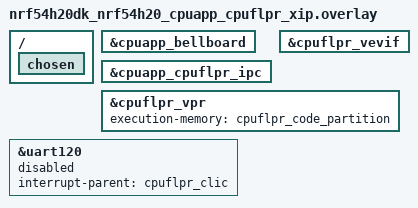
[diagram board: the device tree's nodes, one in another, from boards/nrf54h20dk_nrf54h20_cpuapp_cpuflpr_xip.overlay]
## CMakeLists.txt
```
#
# Copyright (c) 2025 Nordic Semiconductor ASA
#
# SPDX-License-Identifier: Apache-2.0
#

cmake_minimum_required(VERSION 3.20.0)

find_package(Zephyr REQUIRED HINTS $ENV{ZEPHYR_BASE})
project(zbus_ipc_forwarder)

zephyr_library_include_directories(
  src
  common
)

# Define which device this is
zephyr_compile_definitions(ZBUS_DEVICE_A=1)

target_sources(app PRIVATE src/main.c)
```

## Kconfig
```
#
# Copyright (c) 2025 Nordic Semiconductor ASA
#
# SPDX-License-Identifier: Apache-2.0
#

source "Kconfig.zephyr"
```

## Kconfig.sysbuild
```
#
# Copyright (c) 2025 Nordic Semiconductor ASA
#
# SPDX-License-Identifier: Apache-2.0
#

source "share/sysbuild/Kconfig"

choice
	prompt "Remote board target"
	default REMOTE_BOARD_NRF54H20_CPURAD if BOARD = "nrf54h20dk"
	default REMOTE_BOARD_NRF5340_CPUNET if BOARD = "nrf5340dk"

config REMOTE_BOARD_NRF54H20_CPURAD
	bool "nrf54h20dk/nrf54h20/cpurad"

config REMOTE_BOARD_NRF54H20_CPUPPR
	bool "nrf54h20dk/nrf54h20/cpuppr"

config REMOTE_BOARD_NRF54H20_CPUPPR_XIP
	bool "nrf54h20dk/nrf54h20/cpuppr/xip"

## Do not fit on nRF54H20_CPUFLPR without XIP

config REMOTE_BOARD_NRF54H20_CPUFLPR_XIP
	bool "nrf54h20dk/nrf54h20/cpuflpr/xip"

config REMOTE_BOARD_NRF5340_CPUNET
	bool "nrf5340dk/nrf5340/cpunet"

endchoice

config REMOTE_BOARD
	string "The board used for remote target"
	default "nrf54h20dk/nrf54h20/cpurad" if REMOTE_BOARD_NRF54H20_CPURAD
	default "nrf54h20dk/nrf54h20/cpuppr" if REMOTE_BOARD_NRF54H20_CPUPPR
	default "nrf54h20dk/nrf54h20/cpuppr/xip" if REMOTE_BOARD_NRF54H20_CPUPPR_XIP
	default "nrf54h20dk/nrf54h20/cpuflpr/xip" if REMOTE_BOARD_NRF54H20_CPUFLPR_XIP
	default "nrf5340dk/nrf5340/cpunet" if REMOTE_BOARD_NRF5340_CPUNET
```

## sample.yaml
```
sample:
  name: IPC Forwarder
  description: Sample application demonstrating Zbus IPC forwarder functionality.
tests:
  sample.zbus.ipc_forwarder.nrf54h20_cpuapp_cpurad:
    sysbuild: true
    platform_allow:
      - nrf54h20dk/nrf54h20/cpuapp
    extra_args:
      - SNIPPET=nordic-log-stm
      - SB_CONFIG_REMOTE_BOARD_NRF54H20_CPURAD=y
    timeout: 30
    harness: console
    harness_config:
      type: multi_line
      ordered: false
      regex:
        - ".* app/main: Channel request_channel is a master channel"
        - ".* app/main: Channel response_channel is a shadow channel"
        - ".* rad/main: Channel request_channel is a shadow channel"
        - ".* rad/main: Channel response_channel is a master channel"
        - ".* app/main: Published on channel request_channel. Request ID=1, Min=-1, Max=1"
        - ".* rad/main: Received message on channel request_channel"
        - ".* rad/main: Request ID: 1, Min: -1, Max: 1"
        - ".* rad/main: Sending response: ID=1, Value=.*"
        - ".* rad/main: Response published on channel response_channel"
        - ".* app/main: Received message on channel response_channel"
        - ".* app/main: Response ID: 1, Value: .*"

  sample.zbus.ipc_forwarder.nrf54h20_cpuapp_cpuppr:
    sysbuild: true
    platform_allow:
      - nrf54h20dk/nrf54h20/cpuapp
    extra_args:
      - SNIPPET=nordic-log-stm
      - SB_CONFIG_REMOTE_BOARD_NRF54H20_CPUPPR=y
    timeout: 30
    harness: console
    harness_config:
      type: multi_line
      ordered: false
      regex:
        - ".* app/main: Channel request_channel is a master channel"
        - ".* app/main: Channel response_channel is a shadow channel"
        - ".* ppr/main: Channel request_channel is a shadow channel"
        - ".* ppr/main: Channel response_channel is a master channel"
        - ".* app/main: Published on channel request_channel. Request ID=1, Min=-1, Max=1"
        - ".* ppr/main: Received message on channel request_channel"
        - ".* ppr/main: Request ID: 1, Min: -1, Max: 1"
        - ".* ppr/main: Sending response: ID=1, Value=.*"
        - ".* ppr/main: Response published on channel response_channel"
        - ".* app/main: Received message on channel response_channel"
        - ".* app/main: Response ID: 1, Value: .*"

  sample.zbus.ipc_forwarder.nrf54h20_cpuapp_cpuppr_xip:
    sysbuild: true
    platform_allow:
      - nrf54h20dk/nrf54h20/cpuapp
    extra_args:
      - SNIPPET=nordic-log-stm
      - SB_CONFIG_REMOTE_BOARD_NRF54H20_CPUPPR_XIP=y
    timeout: 30
    harness: console
    harness_config:
      type: multi_line
      ordered: false
      regex:
        - ".* app/main: Channel request_channel is a master channel"
        - ".* app/main: Channel response_channel is a shadow channel"
        - ".* ppr/main: Channel request_channel is a shadow channel"
        - ".* ppr/main: Channel response_channel is a master channel"
        - ".* app/main: Published on channel request_channel. Request ID=1, Min=-1, Max=1"
        - ".* ppr/main: Received message on channel request_channel"
        - ".* ppr/main: Request ID: 1, Min: -1, Max: 1"
        - ".* ppr/main: Sending response: ID=1, Value=.*"
        - ".* ppr/main: Response published on channel response_channel"
        - ".* app/main: Received message on channel response_channel"
        - ".* app/main: Response ID: 1, Value: .*"

  sample.zbus.ipc_forwarder.nrf54h20_cpuapp_cpuflpr_xip:
    sysbuild: true
    platform_allow:
      - nrf54h20dk/nrf54h20/cpuapp
    extra_args:
      - SNIPPET=nordic-log-stm
      - SB_CONFIG_REMOTE_BOARD_NRF54H20_CPUFLPR_XIP=y
    timeout: 30
    harness: console
    harness_config:
      type: multi_line
      ordered: false
      regex:
        - ".* app/main: Channel request_channel is a master channel"
        - ".* app/main: Channel response_channel is a shadow channel"
        - ".* flpr/main: Channel request_channel is a shadow channel"
        - ".* flpr/main: Channel response_channel is a master channel"
        - ".* app/main: Published on channel request_channel. Request ID=1, Min=-1, Max=1"
        - ".* flpr/main: Received message on channel request_channel"
        - ".* flpr/main: Request ID: 1, Min: -1, Max: 1"
        - ".* flpr/main: Sending response: ID=1, Value=.*"
        - ".* flpr/main: Response published on channel response_channel"
        - ".* app/main: Received message on channel response_channel"
        - ".* app/main: Response ID: 1, Value: .*"

  sample.zbus.ipc_forwarder.nrf5340_cpuapp_cpunet:
    sysbuild: true
    platform_allow:
      - nrf5340dk/nrf5340/cpuapp
      - nrf5340bsim/nrf5340/cpuapp
    integration_platforms:
      - nrf5340bsim/nrf5340/cpuapp
    tags: ipc
    timeout: 30
    harness: console
    harness_config:
      type: multi_line
      ordered: false
      regex:
        - ".* main: Channel request_channel is a master channel"
        - ".* main: Channel response_channel is a shadow channel"
        - ".* main: Published on channel request_channel. Request ID=1, Min=-1, Max=1"
        - ".* main: Received message on channel response_channel"
        - ".* main: Response ID: 1, Value: .*"
```

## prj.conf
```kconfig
#
# Copyright (c) 2025 Nordic Semiconductor ASA
#
# SPDX-License-Identifier: Apache-2.0
#

CONFIG_LOG=y
# CONFIG_LOG_MODE_MINIMAL=y
CONFIG_LOG_DBG_COLOR_BLUE=y

CONFIG_HEAP_MEM_POOL_SIZE=4096

CONFIG_ZBUS=y
CONFIG_ZBUS_CHANNEL_NAME=y
CONFIG_ZBUS_MSG_SUBSCRIBER=y

CONFIG_CRC=y

CONFIG_MBOX=y
CONFIG_IPC_SERVICE=y

CONFIG_ZBUS_MULTIDOMAIN=y
CONFIG_ZBUS_MULTIDOMAIN_IPC=y
CONFIG_ZBUS_MULTIDOMAIN_LOG_LEVEL_INF=y

# Increase the size of the receive buffer to accommodate larger messages
CONFIG_PBUF_RX_READ_BUF_SIZE=384
```

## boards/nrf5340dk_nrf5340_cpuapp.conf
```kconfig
#
# Copyright (c) 2025 Nordic Semiconductor ASA
#
# SPDX-License-Identifier: Apache-2.0
#

CONFIG_SOC_NRF53_CPUNET_ENABLE=y
```

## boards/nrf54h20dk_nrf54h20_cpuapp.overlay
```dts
/*
 * Copyright (c) 2025 Nordic Semiconductor ASA
 *
 * SPDX-License-Identifier: Apache-2.0
 */

&cpuapp_bellboard {
	status = "okay";
};

/ {
	chosen {
		/delete-property/ zephyr,bt-hci;
	};
};
```

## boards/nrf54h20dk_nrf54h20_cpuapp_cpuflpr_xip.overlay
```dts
/*
 * Copyright (c) 2025 Nordic Semiconductor ASA
 *
 * SPDX-License-Identifier: Apache-2.0
 */

 /* Setup for cpuapp_cpuflpr_ipc */
&cpuapp_bellboard {
	status = "okay";
};

/delete-node/ &cpuapp_cpurad_ipc;

ipc0: &cpuapp_cpuflpr_ipc {
	status = "okay";
};

&cpuflpr_vevif {
	status = "okay";
};

/ {
	chosen {
		/delete-property/ zephyr,bt-hci;
	};
};

/* Necessary for the cpuflpr_xip to work */
&cpuflpr_vpr {
	status = "okay";
	execution-memory = <&cpuflpr_code_partition>;
	/delete-property/ source-memory;
};

&uart120 {
	status = "reserved";
	interrupt-parent = <&cpuflpr_clic>;
};
```

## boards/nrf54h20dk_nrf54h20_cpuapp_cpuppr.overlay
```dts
/*
 * Copyright (c) 2025 Nordic Semiconductor ASA
 *
 * SPDX-License-Identifier: Apache-2.0
 */

 /* Setup for cpuapp_cpuppr_ipc */
&cpuapp_bellboard {
	status = "okay";
};

/delete-node/ &cpuapp_cpurad_ipc;

ipc0: &cpuapp_cpuppr_ipc {
	status = "okay";
};

&cpuppr_vevif {
	status = "okay";
};

/ {
	chosen {
		/delete-property/ zephyr,bt-hci;
	};
};

/* Necessary for the cpuppr to work */
&cpuppr_vpr {
	status = "okay";
};

&uart135 {
	status = "reserved";
};
```

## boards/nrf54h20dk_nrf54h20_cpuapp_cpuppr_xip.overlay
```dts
/*
 * Copyright (c) 2025 Nordic Semiconductor ASA
 *
 * SPDX-License-Identifier: Apache-2.0
 */

 /* Setup for cpuapp_cpuppr_ipc */
&cpuapp_bellboard {
	status = "okay";
};

/delete-node/ &cpuapp_cpurad_ipc;

ipc0: &cpuapp_cpuppr_ipc {
	status = "okay";
};

&cpuppr_vevif {
	status = "okay";
};

/ {
	chosen {
		/delete-property/ zephyr,bt-hci;
	};
};

/* Necessary for the cpuppr_xip to work */
&cpuppr_vpr {
	status = "okay";
	execution-memory = <&cpuppr_code_partition>;
	/delete-property/ source-memory;
};

&uart135 {
	status = "reserved";
};
```

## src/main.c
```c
/*
 * Copyright (c) 2025 Nordic Semiconductor ASA
 *
 * SPDX-License-Identifier: Apache-2.0
 */

#include <zephyr/kernel.h>
#include <zephyr/logging/log.h>
#include <string.h>
#include <zephyr/zbus/zbus.h>
#include <zephyr/zbus/multidomain/zbus_multidomain.h>

#include "common.h"

LOG_MODULE_REGISTER(main, LOG_LEVEL_DBG);

/* NOTE: Shared channels request_channel and response_channel are defined in common.h */

/* Set up proxy agent for ipc0 and add response channel to be forwarded */
#define IPC0_NODE DT_NODELABEL(ipc0)
ZBUS_PROXY_AGENT_DEFINE(ipc_proxy, ZBUS_MULTIDOMAIN_TYPE_IPC, IPC0_NODE);
ZBUS_PROXY_ADD_CHANNEL(ipc_proxy, request_channel);

/* Log response data coming from the response channel */
void ipc_forwarder_listener_cb(const struct zbus_channel *chan)
{
	const struct response_data *data = zbus_chan_const_msg(chan);

	LOG_INF("Received message on channel %s", chan->name);
	LOG_INF("Response ID: %d, Value: %d", data->response_id, data->value);
}

ZBUS_LISTENER_DEFINE(ipc_forwarder_listener, ipc_forwarder_listener_cb);
ZBUS_CHAN_ADD_OBS(response_channel, ipc_forwarder_listener, 0);

bool print_channel_info(const struct zbus_channel *chan)
{
	if (!chan) {
		LOG_ERR("Channel is NULL");
		return false;
	}
	LOG_INF("Channel %s is a %s channel", chan->name,
		ZBUS_CHANNEL_IS_SHADOW(chan) ? "shadow" : "master");
	return true;
}

int main(void)
{
	LOG_INF("ZBUS Multidomain IPC Forwarder Sample Application");
	zbus_iterate_over_channels(print_channel_info);

	struct request_data data = {.request_id = 1, .min_value = -1, .max_value = 1};

	while (1) {
		int ret;

		ret = zbus_chan_pub(&request_channel, &data, K_MSEC(100));
		if (ret < 0) {
			LOG_ERR("Failed to publish on channel %s: %d", request_channel.name, ret);
		} else {
			LOG_INF("Published on channel %s. Request ID=%d, Min=%d, Max=%d",
				request_channel.name, data.request_id, data.min_value,
				data.max_value);
		}

		data.request_id++;
		data.min_value -= 1;
		data.max_value += 1;
		k_sleep(K_SECONDS(5));
	}
	return 0;
}
```
